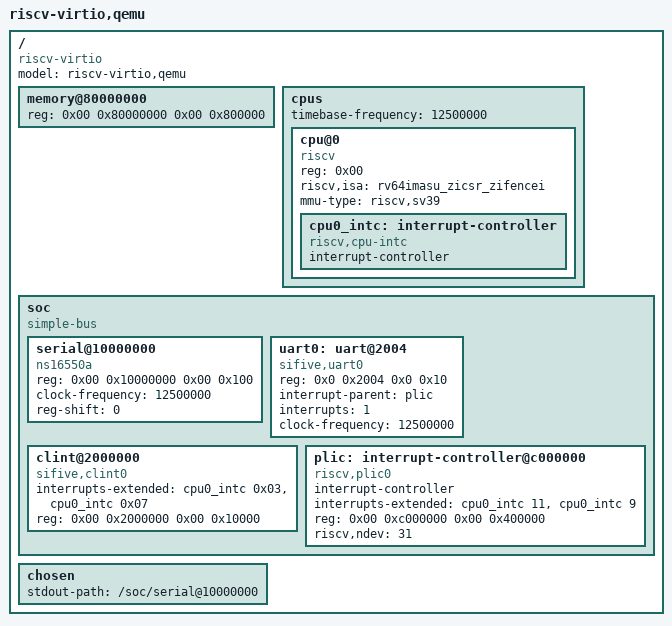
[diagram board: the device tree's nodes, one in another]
/dts-v1/;

/ {
    #address-cells = <0x02>;   // cell is a 32-bit integer, <0x0 0x80000000> is 2 cells
    #size-cells = <0x02>;
    compatible = "riscv-virtio";
    model = "riscv-virtio,qemu";

    /* 1. RAM: 8MB at 0x80000000 */
    memory@80000000 {
        device_type = "memory";
        reg = <0x00 0x80000000 0x00 0x800000>;
    };

    cpus {
        #address-cells = <0x01>;
        #size-cells = <0x00>;
        timebase-frequency = <12500000>;

        cpu@0 {
            phandle = <0x01>;
            device_type = "cpu";
            reg = <0x00>;
            status = "okay";
            compatible = "riscv";
            riscv,isa = "rv64imasu_zicsr_zifencei";
            mmu-type = "riscv,sv39";


            //uart, when meip/seip bell in cpu0_intc, the cause is 11/9, the plic read claim mmio know it's 1 uart. Call uart driver.
            //timer, when mtip/stip bell in cpu0_intc, the cause is 7/5, cpu0_intc know it's clint. Call Clint dirver.
            //soft, when msip/ssip bell in cpu0_intc, the cause is 1/3, cpu0_intc know it's software. Call  software dirver.

            /* INTC: This handles internal interrupts */
            //cpu0_intc is just name of my Trap(meip/seip/mtip/stip/msip/ssip) logic
            cpu0_intc: interrupt-controller { // SoftwareLine IPI/TimeLine/ExternalLine
                #interrupt-cells = <0x01>;
                interrupt-controller;
                compatible = "riscv,cpu-intc";
                phandle = <0x02>; /* This ID is used by CLINT below */
            };
        };
    };


    soc {
        #address-cells = <0x02>;
        #size-cells = <0x02>;
        compatible = "simple-bus";
        ranges;

        /* 2. UART: For QEMU test (at 10000000) */
        serial@10000000 {
            compatible = "ns16550a";
            reg = <0x00 0x10000000 0x00 0x100>;
            clock-frequency = <12500000>;
            reg-shift = <0>;
            status = "okay";
        };
               
        uart0: uart@2004{
             compatible = "sifive,uart0";  // driver
             reg = <0x0 0x2004 0x0 0x10>;
             // if using PLIC point to IRQ 1. If bypass use extended
             //interrupts-extended = <&cpu0_intc 0x09>; // add dummy external interrupt mapping
             interrupt-parent = <&plic>;  
             interrupts = <1>;             // claim number
             clock-frequency = <12500000>;
             //status = "disable";
             status = "okay";
         };

        /* 3. CLINT: Handles Timer AND IPI (Software Interrupt) */
        // Opensbi use this find mtimecmp`
        clint@2000000 {
            /* 0x03 = Software Interrupt, 0x07 = Timer Interrupt */
            interrupts-extended = <&cpu0_intc 0x03 &cpu0_intc 0x07>; /* This links to phandle 0x02 (the CPU INTC) */
            reg = <0x00 0x2000000 0x00 0x10000>;
            compatible = "sifive,clint0", "riscv,clint0";
        };
     
      // device-pending[id]-ctx-meip11-trap(stvec/cpu0_intc) [hardware|software] casue11/9-interruptExtended-plic-driver-claim-knowInterruptType-uartDriver
      // Linux use this to handle harware interrupts
      plic: interrupt-controller@c000000 {  // mmio addr
          compatible = "riscv,plic0"; // pending+0x1000 enable+0x2000 Threshold/Claim+0x200000
          interrupt-controller;
          #interrupt-cells = <1>; // pin style
          #address-cells = <0>; // no sub-address
          // 11 M-External, 9 S-External
          interrupts-extended = <&cpu0_intc 11 &cpu0_intc 9>;  // to  MEIP & SEIP
          reg = <0x00 0xc000000 0x00 0x400000>;
          riscv,ndev = <31>; // Ports/Devices (Plic_pending bit 0 means no interrupt)
          phandle = <0x03>;
     };


    };


    chosen { /* Points to the UART below */
       // qemu
       stdout-path = "/soc/serial@10000000";
       // SoC
       //stdout-path = "/soc/uart@2004";
    };



};
